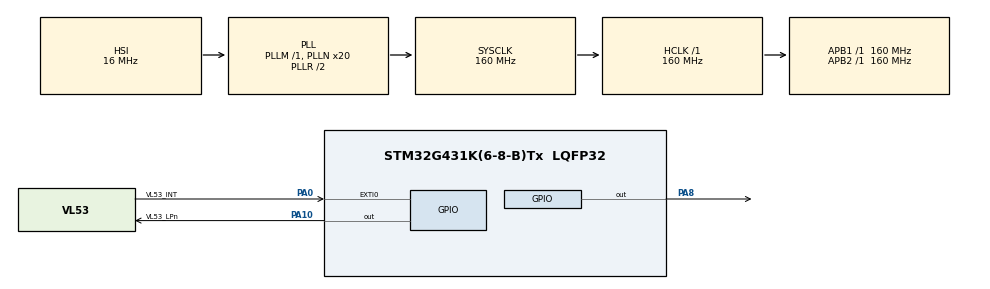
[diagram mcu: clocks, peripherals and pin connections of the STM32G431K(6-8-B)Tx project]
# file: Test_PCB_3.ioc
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Mcu.Family=STM32G4
Mcu.Name=STM32G431K(6-8-B)Tx
Mcu.Package=LQFP32
NVIC.EXTI0_IRQn=true\:0\:0\:false\:false\:true\:true\:true\:true
NVIC.PriorityGroup=NVIC_PRIORITYGROUP_4
PA0.GPIO_Label=VL53_INT
PA0.GPIO_ModeDefaultEXTI=GPIO_MODE_IT_FALLING
PA0.GPIO_PuPd=GPIO_PULLUP
PA0.Signal=GPXTI0
PA10.GPIO_Label=VL53_LPn
PA10.Signal=GPIO_Output
PA8.Signal=GPIO_Output
ProjectManager.HeapSize=0x200
ProjectManager.StackSize=0x400
ProjectManager.TargetToolchain=STM32CubeIDE
RCC.ADC12Freq_Value=160000000
RCC.AHBFreq_Value=160000000
RCC.APB1Freq_Value=160000000
RCC.APB1TimFreq_Value=160000000
RCC.APB2Freq_Value=160000000
RCC.APB2TimFreq_Value=160000000
RCC.CortexFreq_Value=160000000
RCC.EXTERNAL_CLOCK_VALUE=12288000
RCC.HCLKFreq_Value=160000000
RCC.HSE_VALUE=8000000
RCC.HSI48_VALUE=48000000
RCC.HSI_VALUE=16000000
RCC.LSE_VALUE=32768
RCC.PLLN=20
RCC.SYSCLKFreq_VALUE=160000000
RCC.SYSCLKSource=RCC_SYSCLKSOURCE_PLLCLK
RCC.USBFreq_Value=160000000
RCC.VCOOutputFreq_Value=320000000
VP_SYS_VS_DBSignals.Mode=DisableDeadBatterySignals
board=custom

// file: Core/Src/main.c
/* USER CODE BEGIN Header */
/**
  ******************************************************************************
  * @file           : main.c
  * @brief          : Main program body
  ******************************************************************************
  * @attention
  *
  * Copyright (c) 2026 STMicroelectronics.
  * All rights reserved.
  *
  * This software is licensed under terms that can be found in the LICENSE file
  * in the root directory of this software component.
  * If no LICENSE file comes with this software, it is provided AS-IS.
  *
  ******************************************************************************
  */
/* USER CODE END Header */
#include "main.h"
#include "stm32g4xx_hal_conf.h"

void SystemClock_Config(void);
static void MX_GPIO_Init(void);

int main(void)
{

  /* MCU Configuration--------------------------------------------------------*/

  /* Reset of all peripherals, Initializes the Flash interface and the Systick. */
  HAL_Init();

  /* Configure the system clock */
  SystemClock_Config();

  /* Initialize all configured peripherals */
  MX_GPIO_Init();

  /* Infinite loop */
  while (1)
  {

    /* USER CODE BEGIN 3 */
	  HAL_GPIO_WritePin(GPIOA, GPIO_PIN_8, GPIO_PIN_SET); // Force l'allumage permanent
  }
  /* USER CODE END 3 */
}

void SystemClock_Config(void)
{
  RCC_OscInitTypeDef RCC_OscInitStruct = {0};
  RCC_ClkInitTypeDef RCC_ClkInitStruct = {0};

  /** Configure the main internal regulator output voltage
  */
  HAL_PWREx_ControlVoltageScaling(PWR_REGULATOR_VOLTAGE_SCALE1_BOOST);

  /** Initializes the RCC Oscillators according to the specified parameters
  * in the RCC_OscInitTypeDef structure.
  */
  RCC_OscInitStruct.OscillatorType = RCC_OSCILLATORTYPE_HSI;
  RCC_OscInitStruct.HSIState = RCC_HSI_ON;
  RCC_OscInitStruct.HSICalibrationValue = RCC_HSICALIBRATION_DEFAULT;
  RCC_OscInitStruct.PLL.PLLState = RCC_PLL_ON;
  RCC_OscInitStruct.PLL.PLLSource = RCC_PLLSOURCE_HSI;
  RCC_OscInitStruct.PLL.PLLM = RCC_PLLM_DIV1;
  RCC_OscInitStruct.PLL.PLLN = 20;
  RCC_OscInitStruct.PLL.PLLP = RCC_PLLP_DIV2;
  RCC_OscInitStruct.PLL.PLLQ = RCC_PLLQ_DIV2;
  RCC_OscInitStruct.PLL.PLLR = RCC_PLLR_DIV2;
  if (HAL_RCC_OscConfig(&RCC_OscInitStruct) != HAL_OK)
  {
    Error_Handler();
  }

  /** Initializes the CPU, AHB and APB buses clocks
  */
  RCC_ClkInitStruct.ClockType = RCC_CLOCKTYPE_HCLK|RCC_CLOCKTYPE_SYSCLK
                              |RCC_CLOCKTYPE_PCLK1|RCC_CLOCKTYPE_PCLK2;
  RCC_ClkInitStruct.SYSCLKSource = RCC_SYSCLKSOURCE_PLLCLK;
  RCC_ClkInitStruct.AHBCLKDivider = RCC_SYSCLK_DIV1;
  RCC_ClkInitStruct.APB1CLKDivider = RCC_HCLK_DIV1;
  RCC_ClkInitStruct.APB2CLKDivider = RCC_HCLK_DIV1;

  if (HAL_RCC_ClockConfig(&RCC_ClkInitStruct, FLASH_LATENCY_4) != HAL_OK)
  {
    Error_Handler();
  }
}

static void MX_GPIO_Init(void)
{
  GPIO_InitTypeDef GPIO_InitStruct = {0};

  /* GPIO Ports Clock Enable */
  __HAL_RCC_GPIOA_CLK_ENABLE();

  /*Configure GPIO pin Output Level */
  HAL_GPIO_WritePin(GPIOA, GPIO_PIN_8|VL53_LPn_Pin, GPIO_PIN_RESET);

  /*Configure GPIO pin : VL53_INT_Pin */
  GPIO_InitStruct.Pin = VL53_INT_Pin;
  GPIO_InitStruct.Mode = GPIO_MODE_IT_FALLING;
  GPIO_InitStruct.Pull = GPIO_PULLUP;
  HAL_GPIO_Init(VL53_INT_GPIO_Port, &GPIO_InitStruct);

  /*Configure GPIO pins : PA8 VL53_LPn_Pin */
  GPIO_InitStruct.Pin = GPIO_PIN_8|VL53_LPn_Pin;
  GPIO_InitStruct.Mode = GPIO_MODE_OUTPUT_PP;
  GPIO_InitStruct.Pull = GPIO_NOPULL;
  GPIO_InitStruct.Speed = GPIO_SPEED_FREQ_LOW;
  HAL_GPIO_Init(GPIOA, &GPIO_InitStruct);

  /* EXTI interrupt init*/
  HAL_NVIC_SetPriority(EXTI0_IRQn, 0, 0);
  HAL_NVIC_EnableIRQ(EXTI0_IRQn);

}

void Error_Handler(void)
{
  __disable_irq();
  while (1)
  {
  }
}
